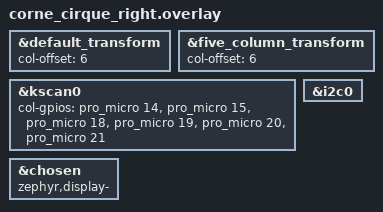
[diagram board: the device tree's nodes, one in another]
/*
 * Copyright (c) 2020 Pete Johanson
 *
 * SPDX-License-Identifier: MIT
 */
#include <input/processors.dtsi>
#include <dt-bindings/zmk/input_transform.h>
#include <behaviors/input_processor_gestures.dtsi>
#include <behaviors/input_processor_absolute_to_relative.dtsi>
#include "corne_cirque.dtsi"

&default_transform {
    col-offset = <6>;
};

&five_column_transform {
    col-offset = <6>;
};

&kscan0 {
    col-gpios
        = <&pro_micro 14 GPIO_ACTIVE_HIGH>
        , <&pro_micro 15 GPIO_ACTIVE_HIGH>
        , <&pro_micro 18 GPIO_ACTIVE_HIGH>
        , <&pro_micro 19 GPIO_ACTIVE_HIGH>
        , <&pro_micro 20 GPIO_ACTIVE_HIGH>
        , <&pro_micro 21 GPIO_ACTIVE_HIGH>
        ;
};


&chosen {
   zephyr,display-;
};



&i2c0 {
    status = "okay";
};

/* glidepoint/virtual-input removed on right side */
